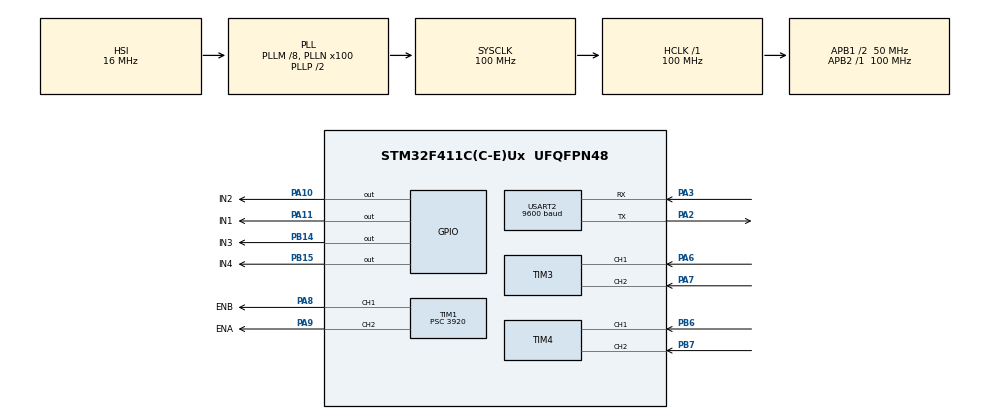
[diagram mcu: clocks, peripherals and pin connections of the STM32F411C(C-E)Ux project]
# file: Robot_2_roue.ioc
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Mcu.Family=STM32F4
Mcu.Name=STM32F411C(C-E)Ux
Mcu.Package=UFQFPN48
NVIC.PriorityGroup=NVIC_PRIORITYGROUP_4
NVIC.TIM1_BRK_TIM9_IRQn=true\:0\:0\:false\:false\:true\:true\:true\:true
NVIC.USART2_IRQn=true\:0\:0\:false\:false\:true\:true\:true\:true
PA10.GPIO_Label=IN2
PA10.Signal=GPIO_Output
PA11.GPIO_Label=IN1
PA11.Signal=GPIO_Output
PA2.Mode=Asynchronous
PA2.Signal=USART2_TX
PA3.Mode=Asynchronous
PA3.Signal=USART2_RX
PA6.Signal=S_TIM3_CH1
PA7.Signal=S_TIM3_CH2
PA8.GPIO_Label=ENB
PA8.Signal=S_TIM1_CH1
PA9.GPIO_Label=ENA
PA9.Signal=S_TIM1_CH2
PB14.GPIO_Label=IN3
PB14.Signal=GPIO_Output
PB15.GPIO_Label=IN4
PB15.Signal=GPIO_Output
PB6.Signal=S_TIM4_CH1
PB7.Signal=S_TIM4_CH2
ProjectManager.HeapSize=0x200
ProjectManager.StackSize=0x400
ProjectManager.TargetToolchain=STM32CubeIDE
RCC.48MHZClocksFreq_Value=50000000
RCC.AHBFreq_Value=100000000
RCC.APB1CLKDivider=RCC_HCLK_DIV2
RCC.APB1Freq_Value=50000000
RCC.APB1TimFreq_Value=100000000
RCC.APB2Freq_Value=100000000
RCC.APB2TimFreq_Value=100000000
RCC.CortexFreq_Value=100000000
RCC.HCLKFreq_Value=100000000
RCC.HSE_VALUE=25000000
RCC.HSI_VALUE=16000000
RCC.LSE_VALUE=32768
RCC.PLLM=8
RCC.PLLN=100
RCC.SYSCLKFreq_VALUE=100000000
RCC.SYSCLKSource=RCC_SYSCLKSOURCE_PLLCLK
RCC.VCOOutputFreq_Value=200000000
SH.S_TIM1_CH1.0=TIM1_CH1,PWM Generation1 CH1
SH.S_TIM1_CH2.0=TIM1_CH2,PWM Generation2 CH2
SH.S_TIM3_CH1.0=TIM3_CH1,Encoder_Interface
SH.S_TIM3_CH2.0=TIM3_CH2,Encoder_Interface
SH.S_TIM4_CH1.0=TIM4_CH1,Encoder_Interface
SH.S_TIM4_CH2.0=TIM4_CH2,Encoder_Interface
TIM1.Channel-PWM\ Generation1\ CH1=TIM_CHANNEL_1
TIM1.Channel-PWM\ Generation2\ CH2=TIM_CHANNEL_2
TIM1.Period=255
TIM1.Prescaler=3920
TIM3.EncoderMode=TIM_ENCODERMODE_TI12
TIM4.EncoderMode=TIM_ENCODERMODE_TI12
TIM9.Period=999
TIM9.Prescaler=999
USART2.BaudRate=9600
USART2.Mode=MODE_TX_RX
USART2.VirtualMode=VM_ASYNC
VP_TIM9_VS_ClockSourceINT.Mode=Internal
board=custom

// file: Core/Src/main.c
/* USER CODE BEGIN Header */
/**
  ******************************************************************************
  * @file           : main.c
  * @brief          : Main program body
  ******************************************************************************
  * @attention
  *
  * Copyright (c) 2025 STMicroelectronics.
  * All rights reserved.
  *
  * This software is licensed under terms that can be found in the LICENSE file
  * in the root directory of this software component.
  * If no LICENSE file comes with this software, it is provided AS-IS.
  *
  ******************************************************************************
  */
/* USER CODE END Header */
#include "main.h"

/* USER CODE BEGIN Includes */
#include "../Fonction_Sup/Programme_Principale.h"
/* USER CODE END Includes */

TIM_HandleTypeDef htim1;
TIM_HandleTypeDef htim3;
TIM_HandleTypeDef htim4;
TIM_HandleTypeDef htim9;

UART_HandleTypeDef huart2;

void SystemClock_Config(void);
static void MX_GPIO_Init(void);
static void MX_TIM3_Init(void);
static void MX_TIM4_Init(void);
static void MX_TIM1_Init(void);
static void MX_TIM9_Init(void);
static void MX_USART2_UART_Init(void);

int main(void)
{

  /* MCU Configuration--------------------------------------------------------*/

  /* Reset of all peripherals, Initializes the Flash interface and the Systick. */
  HAL_Init();

  /* Configure the system clock */
  SystemClock_Config();

  /* Initialize all configured peripherals */
  MX_GPIO_Init();
  MX_TIM3_Init();
  MX_TIM4_Init();
  MX_TIM1_Init();
  MX_TIM9_Init();
  MX_USART2_UART_Init();
  /* USER CODE BEGIN 2 */
  Initialisation();
  /* USER CODE END 2 */

  /* Infinite loop */
  while (1)
  {

    /* USER CODE BEGIN 3 */
	  Programme_Principale();
  }
  /* USER CODE END 3 */
}

void SystemClock_Config(void)
{
  RCC_OscInitTypeDef RCC_OscInitStruct = {0};
  RCC_ClkInitTypeDef RCC_ClkInitStruct = {0};

  /** Configure the main internal regulator output voltage
  */
  __HAL_RCC_PWR_CLK_ENABLE();
  __HAL_PWR_VOLTAGESCALING_CONFIG(PWR_REGULATOR_VOLTAGE_SCALE1);

  /** Initializes the RCC Oscillators according to the specified parameters
  * in the RCC_OscInitTypeDef structure.
  */
  RCC_OscInitStruct.OscillatorType = RCC_OSCILLATORTYPE_HSI;
  RCC_OscInitStruct.HSIState = RCC_HSI_ON;
  RCC_OscInitStruct.HSICalibrationValue = RCC_HSICALIBRATION_DEFAULT;
  RCC_OscInitStruct.PLL.PLLState = RCC_PLL_ON;
  RCC_OscInitStruct.PLL.PLLSource = RCC_PLLSOURCE_HSI;
  RCC_OscInitStruct.PLL.PLLM = 8;
  RCC_OscInitStruct.PLL.PLLN = 100;
  RCC_OscInitStruct.PLL.PLLP = RCC_PLLP_DIV2;
  RCC_OscInitStruct.PLL.PLLQ = 4;
  if (HAL_RCC_OscConfig(&RCC_OscInitStruct) != HAL_OK)
  {
    Error_Handler();
  }

  /** Initializes the CPU, AHB and APB buses clocks
  */
  RCC_ClkInitStruct.ClockType = RCC_CLOCKTYPE_HCLK|RCC_CLOCKTYPE_SYSCLK
                              |RCC_CLOCKTYPE_PCLK1|RCC_CLOCKTYPE_PCLK2;
  RCC_ClkInitStruct.SYSCLKSource = RCC_SYSCLKSOURCE_PLLCLK;
  RCC_ClkInitStruct.AHBCLKDivider = RCC_SYSCLK_DIV1;
  RCC_ClkInitStruct.APB1CLKDivider = RCC_HCLK_DIV2;
  RCC_ClkInitStruct.APB2CLKDivider = RCC_HCLK_DIV1;

  if (HAL_RCC_ClockConfig(&RCC_ClkInitStruct, FLASH_LATENCY_3) != HAL_OK)
  {
    Error_Handler();
  }
}

static void MX_TIM1_Init(void)
{

  TIM_MasterConfigTypeDef sMasterConfig = {0};
  TIM_OC_InitTypeDef sConfigOC = {0};
  TIM_BreakDeadTimeConfigTypeDef sBreakDeadTimeConfig = {0};

  htim1.Instance = TIM1;
  htim1.Init.Prescaler = 3920;
  htim1.Init.CounterMode = TIM_COUNTERMODE_UP;
  htim1.Init.Period = 255;
  htim1.Init.ClockDivision = TIM_CLOCKDIVISION_DIV1;
  htim1.Init.RepetitionCounter = 0;
  htim1.Init.AutoReloadPreload = TIM_AUTORELOAD_PRELOAD_DISABLE;
  if (HAL_TIM_PWM_Init(&htim1) != HAL_OK)
  {
    Error_Handler();
  }
  sMasterConfig.MasterOutputTrigger = TIM_TRGO_RESET;
  sMasterConfig.MasterSlaveMode = TIM_MASTERSLAVEMODE_DISABLE;
  if (HAL_TIMEx_MasterConfigSynchronization(&htim1, &sMasterConfig) != HAL_OK)
  {
    Error_Handler();
  }
  sConfigOC.OCMode = TIM_OCMODE_PWM1;
  sConfigOC.Pulse = 0;
  sConfigOC.OCPolarity = TIM_OCPOLARITY_HIGH;
  sConfigOC.OCNPolarity = TIM_OCNPOLARITY_HIGH;
  sConfigOC.OCFastMode = TIM_OCFAST_DISABLE;
  sConfigOC.OCIdleState = TIM_OCIDLESTATE_RESET;
  sConfigOC.OCNIdleState = TIM_OCNIDLESTATE_RESET;
  if (HAL_TIM_PWM_ConfigChannel(&htim1, &sConfigOC, TIM_CHANNEL_1) != HAL_OK)
  {
    Error_Handler();
  }
  if (HAL_TIM_PWM_ConfigChannel(&htim1, &sConfigOC, TIM_CHANNEL_2) != HAL_OK)
  {
    Error_Handler();
  }
  sBreakDeadTimeConfig.OffStateRunMode = TIM_OSSR_DISABLE;
  sBreakDeadTimeConfig.OffStateIDLEMode = TIM_OSSI_DISABLE;
  sBreakDeadTimeConfig.LockLevel = TIM_LOCKLEVEL_OFF;
  sBreakDeadTimeConfig.DeadTime = 0;
  sBreakDeadTimeConfig.BreakState = TIM_BREAK_DISABLE;
  sBreakDeadTimeConfig.BreakPolarity = TIM_BREAKPOLARITY_HIGH;
  sBreakDeadTimeConfig.AutomaticOutput = TIM_AUTOMATICOUTPUT_DISABLE;
  if (HAL_TIMEx_ConfigBreakDeadTime(&htim1, &sBreakDeadTimeConfig) != HAL_OK)
  {
    Error_Handler();
  }
  HAL_TIM_MspPostInit(&htim1);

}

static void MX_TIM3_Init(void)
{

  TIM_Encoder_InitTypeDef sConfig = {0};
  TIM_MasterConfigTypeDef sMasterConfig = {0};

  htim3.Instance = TIM3;
  htim3.Init.Prescaler = 0;
  htim3.Init.CounterMode = TIM_COUNTERMODE_UP;
  htim3.Init.Period = 65535;
  htim3.Init.ClockDivision = TIM_CLOCKDIVISION_DIV1;
  htim3.Init.AutoReloadPreload = TIM_AUTORELOAD_PRELOAD_DISABLE;
  sConfig.EncoderMode = TIM_ENCODERMODE_TI12;
  sConfig.IC1Polarity = TIM_ICPOLARITY_RISING;
  sConfig.IC1Selection = TIM_ICSELECTION_DIRECTTI;
  sConfig.IC1Prescaler = TIM_ICPSC_DIV1;
  sConfig.IC1Filter = 0;
  sConfig.IC2Polarity = TIM_ICPOLARITY_RISING;
  sConfig.IC2Selection = TIM_ICSELECTION_DIRECTTI;
  sConfig.IC2Prescaler = TIM_ICPSC_DIV1;
  sConfig.IC2Filter = 0;
  if (HAL_TIM_Encoder_Init(&htim3, &sConfig) != HAL_OK)
  {
    Error_Handler();
  }
  sMasterConfig.MasterOutputTrigger = TIM_TRGO_RESET;
  sMasterConfig.MasterSlaveMode = TIM_MASTERSLAVEMODE_DISABLE;
  if (HAL_TIMEx_MasterConfigSynchronization(&htim3, &sMasterConfig) != HAL_OK)
  {
    Error_Handler();
  }

}

static void MX_TIM4_Init(void)
{

  TIM_Encoder_InitTypeDef sConfig = {0};
  TIM_MasterConfigTypeDef sMasterConfig = {0};

  htim4.Instance = TIM4;
  htim4.Init.Prescaler = 0;
  htim4.Init.CounterMode = TIM_COUNTERMODE_UP;
  htim4.Init.Period = 65535;
  htim4.Init.ClockDivision = TIM_CLOCKDIVISION_DIV1;
  htim4.Init.AutoReloadPreload = TIM_AUTORELOAD_PRELOAD_DISABLE;
  sConfig.EncoderMode = TIM_ENCODERMODE_TI12;
  sConfig.IC1Polarity = TIM_ICPOLARITY_RISING;
  sConfig.IC1Selection = TIM_ICSELECTION_DIRECTTI;
  sConfig.IC1Prescaler = TIM_ICPSC_DIV1;
  sConfig.IC1Filter = 0;
  sConfig.IC2Polarity = TIM_ICPOLARITY_RISING;
  sConfig.IC2Selection = TIM_ICSELECTION_DIRECTTI;
  sConfig.IC2Prescaler = TIM_ICPSC_DIV1;
  sConfig.IC2Filter = 0;
  if (HAL_TIM_Encoder_Init(&htim4, &sConfig) != HAL_OK)
  {
    Error_Handler();
  }
  sMasterConfig.MasterOutputTrigger = TIM_TRGO_RESET;
  sMasterConfig.MasterSlaveMode = TIM_MASTERSLAVEMODE_DISABLE;
  if (HAL_TIMEx_MasterConfigSynchronization(&htim4, &sMasterConfig) != HAL_OK)
  {
    Error_Handler();
  }

}

static void MX_TIM9_Init(void)
{

  TIM_ClockConfigTypeDef sClockSourceConfig = {0};

  htim9.Instance = TIM9;
  htim9.Init.Prescaler = 999;
  htim9.Init.CounterMode = TIM_COUNTERMODE_UP;
  htim9.Init.Period = 999;
  htim9.Init.ClockDivision = TIM_CLOCKDIVISION_DIV1;
  htim9.Init.AutoReloadPreload = TIM_AUTORELOAD_PRELOAD_DISABLE;
  if (HAL_TIM_Base_Init(&htim9) != HAL_OK)
  {
    Error_Handler();
  }
  sClockSourceConfig.ClockSource = TIM_CLOCKSOURCE_INTERNAL;
  if (HAL_TIM_ConfigClockSource(&htim9, &sClockSourceConfig) != HAL_OK)
  {
    Error_Handler();
  }

}

static void MX_USART2_UART_Init(void)
{

  huart2.Instance = USART2;
  huart2.Init.BaudRate = 9600;
  huart2.Init.WordLength = UART_WORDLENGTH_8B;
  huart2.Init.StopBits = UART_STOPBITS_1;
  huart2.Init.Parity = UART_PARITY_NONE;
  huart2.Init.Mode = UART_MODE_TX_RX;
  huart2.Init.HwFlowCtl = UART_HWCONTROL_NONE;
  huart2.Init.OverSampling = UART_OVERSAMPLING_16;
  if (HAL_UART_Init(&huart2) != HAL_OK)
  {
    Error_Handler();
  }

}

static void MX_GPIO_Init(void)
{
  GPIO_InitTypeDef GPIO_InitStruct = {0};

  /* GPIO Ports Clock Enable */
  __HAL_RCC_GPIOA_CLK_ENABLE();
  __HAL_RCC_GPIOB_CLK_ENABLE();

  /*Configure GPIO pin Output Level */
  HAL_GPIO_WritePin(GPIOB, IN3_Pin|IN4_Pin, GPIO_PIN_RESET);

  /*Configure GPIO pin Output Level */
  HAL_GPIO_WritePin(GPIOA, IN2_Pin|IN1_Pin, GPIO_PIN_RESET);

  /*Configure GPIO pins : IN3_Pin IN4_Pin */
  GPIO_InitStruct.Pin = IN3_Pin|IN4_Pin;
  GPIO_InitStruct.Mode = GPIO_MODE_OUTPUT_PP;
  GPIO_InitStruct.Pull = GPIO_NOPULL;
  GPIO_InitStruct.Speed = GPIO_SPEED_FREQ_LOW;
  HAL_GPIO_Init(GPIOB, &GPIO_InitStruct);

  /*Configure GPIO pins : IN2_Pin IN1_Pin */
  GPIO_InitStruct.Pin = IN2_Pin|IN1_Pin;
  GPIO_InitStruct.Mode = GPIO_MODE_OUTPUT_PP;
  GPIO_InitStruct.Pull = GPIO_NOPULL;
  GPIO_InitStruct.Speed = GPIO_SPEED_FREQ_LOW;
  HAL_GPIO_Init(GPIOA, &GPIO_InitStruct);

}

void Error_Handler(void)
{
  __disable_irq();
  while (1)
  {
  }
}
